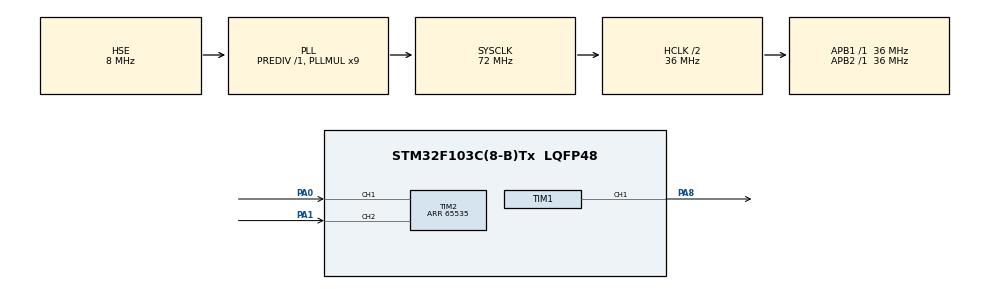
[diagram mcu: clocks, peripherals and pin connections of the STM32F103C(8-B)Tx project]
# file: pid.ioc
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FREERTOS.Tasks01=defaultTask,0,128,StartDefaultTask,Default,NULL
FREERTOS.configTOTAL_HEAP_SIZE=10240
FREERTOS.configUSE_TIMERS=0
Mcu.Family=STM32F1
Mcu.Name=STM32F103C(8-B)Tx
Mcu.Package=LQFP48
NVIC.PriorityGroup=NVIC_PRIORITYGROUP_4
NVIC.TIM2_IRQn=true\:5\:0\:false\:false\:true\:true\:true
PA0-WKUP.Signal=S_TIM2_CH1_ETR
PA1.Signal=S_TIM2_CH2
PA13.Mode=Serial_Wire
PA13.Signal=SYS_JTMS-SWDIO
PA14.Mode=Serial_Wire
PA14.Signal=SYS_JTCK-SWCLK
PA8.Signal=S_TIM1_CH1
PD0-OSC_IN.Mode=HSE-External-Oscillator
PD0-OSC_IN.Signal=RCC_OSC_IN
PD1-OSC_OUT.Mode=HSE-External-Oscillator
PD1-OSC_OUT.Signal=RCC_OSC_OUT
ProjectManager.HeapSize=0x00
ProjectManager.StackSize=0x400
ProjectManager.TargetToolchain=EWARM
RCC.AHBCLKDivider=RCC_SYSCLK_DIV2
RCC.AHBFreq_Value=36000000
RCC.APB1Freq_Value=36000000
RCC.APB1TimFreq_Value=36000000
RCC.APB2Freq_Value=36000000
RCC.APB2TimFreq_Value=36000000
RCC.HCLKFreq_Value=36000000
RCC.PLLMUL=RCC_PLL_MUL9
RCC.PLLSourceVirtual=RCC_PLLSOURCE_HSE
RCC.SYSCLKFreq_VALUE=72000000
RCC.SYSCLKSource=RCC_SYSCLKSOURCE_PLLCLK
RCC.USBFreq_Value=72000000
SH.S_TIM1_CH1.0=TIM1_CH1,PWM Generation1 CH1
SH.S_TIM2_CH1_ETR.0=TIM2_CH1,Encoder_Interface
SH.S_TIM2_CH2.0=TIM2_CH2,Encoder_Interface
TIM1.Channel-PWM\ Generation1\ CH1=TIM_CHANNEL_1
TIM1.Period=999
TIM1.Prescaler=71
TIM2.EncoderMode=TIM_ENCODERMODE_TI12
TIM2.IC1Polarity=TIM_ICPOLARITY_BOTHEDGE
TIM2.IC2Polarity=TIM_ICPOLARITY_BOTHEDGE
TIM2.Period=65535
VP_FREERTOS_VS_ENABLE.Mode=Enabled
board=pid

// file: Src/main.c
/**
  ******************************************************************************
  * File Name          : main.c
  * Description        : Main program body
  ******************************************************************************
  * This notice applies to any and all portions of this file
  * that are not between comment pairs USER CODE BEGIN and
  * USER CODE END. Other portions of this file, whether
  * inserted by the user or by software development tools
  * are owned by their respective copyright owners.
  *
  * Copyright (c) 2017 STMicroelectronics International N.V.
  * All rights reserved.
  *
  * Redistribution and use in source and binary forms, with or without
  * modification, are permitted, provided that the following conditions are met:
  *
  * 1. Redistribution of source code must retain the above copyright notice,
  *    this list of conditions and the following disclaimer.
  * 2. Redistributions in binary form must reproduce the above copyright notice,
  *    this list of conditions and the following disclaimer in the documentation
  *    and/or other materials provided with the distribution.
  * 3. Neither the name of STMicroelectronics nor the names of other
  *    contributors to this software may be used to endorse or promote products
  *    derived from this software without specific written permission.
  * 4. This software, including modifications and/or derivative works of this
  *    software, must execute solely and exclusively on microcontroller or
  *    microprocessor devices manufactured by or for STMicroelectronics.
  * 5. Redistribution and use of this software other than as permitted under
  *    this license is void and will automatically terminate your rights under
  *    this license.
  *
  * THIS SOFTWARE IS PROVIDED BY STMICROELECTRONICS AND CONTRIBUTORS "AS IS"
  * AND ANY EXPRESS, IMPLIED OR STATUTORY WARRANTIES, INCLUDING, BUT NOT
  * LIMITED TO, THE IMPLIED WARRANTIES OF MERCHANTABILITY, FITNESS FOR A
  * PARTICULAR PURPOSE AND NON-INFRINGEMENT OF THIRD PARTY INTELLECTUAL PROPERTY
  * RIGHTS ARE DISCLAIMED TO THE FULLEST EXTENT PERMITTED BY LAW. IN NO EVENT
  * SHALL STMICROELECTRONICS OR CONTRIBUTORS BE LIABLE FOR ANY DIRECT, INDIRECT,
  * INCIDENTAL, SPECIAL, EXEMPLARY, OR CONSEQUENTIAL DAMAGES (INCLUDING, BUT NOT
  * LIMITED TO, PROCUREMENT OF SUBSTITUTE GOODS OR SERVICES; LOSS OF USE, DATA,
  * OR PROFITS; OR BUSINESS INTERRUPTION) HOWEVER CAUSED AND ON ANY THEORY OF
  * LIABILITY, WHETHER IN CONTRACT, STRICT LIABILITY, OR TORT (INCLUDING
  * NEGLIGENCE OR OTHERWISE) ARISING IN ANY WAY OUT OF THE USE OF THIS SOFTWARE,
  * EVEN IF ADVISED OF THE POSSIBILITY OF SUCH DAMAGE.
  *
  ******************************************************************************
  */

#include "main.h"
#include "stm32f1xx_hal.h"
#include "cmsis_os.h"
#include "tim.h"
#include "gpio.h"

/* USER CODE BEGIN PV */
/* Private variables ---------------------------------------------------------*/

/* USER CODE END PV */

void SystemClock_Config(void);
void MX_FREERTOS_Init(void);

/* USER CODE BEGIN PFP */
/* Private function prototypes -----------------------------------------------*/

/* USER CODE END PFP */

int main(void)
{

  /* MCU Configuration----------------------------------------------------------*/

  /* Reset of all peripherals, Initializes the Flash interface and the Systick. */
  HAL_Init();

  /* Configure the system clock */
  SystemClock_Config();

  /* Initialize all configured peripherals */
  MX_GPIO_Init();
  MX_TIM2_Init();
  MX_TIM1_Init();

  /* Call init function for freertos objects (in freertos.c) */
  MX_FREERTOS_Init();

  /* Start scheduler */
  osKernelStart();

  /* We should never get here as control is now taken by the scheduler */

  /* Infinite loop */
  while (1)
  {

  }

}

/** System Clock Configuration
*/
void SystemClock_Config(void)
{

  RCC_OscInitTypeDef RCC_OscInitStruct;
  RCC_ClkInitTypeDef RCC_ClkInitStruct;

    /**Initializes the CPU, AHB and APB busses clocks
    */
  RCC_OscInitStruct.OscillatorType = RCC_OSCILLATORTYPE_HSE;
  RCC_OscInitStruct.HSEState = RCC_HSE_ON;
  RCC_OscInitStruct.HSEPredivValue = RCC_HSE_PREDIV_DIV1;
  RCC_OscInitStruct.HSIState = RCC_HSI_ON;
  RCC_OscInitStruct.PLL.PLLState = RCC_PLL_ON;
  RCC_OscInitStruct.PLL.PLLSource = RCC_PLLSOURCE_HSE;
  RCC_OscInitStruct.PLL.PLLMUL = RCC_PLL_MUL9;
  if (HAL_RCC_OscConfig(&RCC_OscInitStruct) != HAL_OK)
  {
    _Error_Handler(__FILE__, __LINE__);
  }

    /**Initializes the CPU, AHB and APB busses clocks
    */
  RCC_ClkInitStruct.ClockType = RCC_CLOCKTYPE_HCLK|RCC_CLOCKTYPE_SYSCLK
                              |RCC_CLOCKTYPE_PCLK1|RCC_CLOCKTYPE_PCLK2;
  RCC_ClkInitStruct.SYSCLKSource = RCC_SYSCLKSOURCE_PLLCLK;
  RCC_ClkInitStruct.AHBCLKDivider = RCC_SYSCLK_DIV2;
  RCC_ClkInitStruct.APB1CLKDivider = RCC_HCLK_DIV1;
  RCC_ClkInitStruct.APB2CLKDivider = RCC_HCLK_DIV1;

  if (HAL_RCC_ClockConfig(&RCC_ClkInitStruct, FLASH_LATENCY_2) != HAL_OK)
  {
    _Error_Handler(__FILE__, __LINE__);
  }

    /**Configure the Systick interrupt time
    */
  HAL_SYSTICK_Config(HAL_RCC_GetHCLKFreq()/1000);

    /**Configure the Systick
    */
  HAL_SYSTICK_CLKSourceConfig(SYSTICK_CLKSOURCE_HCLK);

  /* SysTick_IRQn interrupt configuration */
  HAL_NVIC_SetPriority(SysTick_IRQn, 15, 0);
}

void _Error_Handler(char * file, int line)
{
  while(1)
  {
  }
}

/************************ (C) COPYRIGHT STMicroelectronics *****END OF FILE****/

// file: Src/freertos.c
/**
  ******************************************************************************
  * File Name          : freertos.c
  * Description        : Code for freertos applications
  ******************************************************************************
  * This notice applies to any and all portions of this file
  * that are not between comment pairs USER CODE BEGIN and
  * USER CODE END. Other portions of this file, whether
  * inserted by the user or by software development tools
  * are owned by their respective copyright owners.
  *
  * Copyright (c) 2017 STMicroelectronics International N.V.
  * All rights reserved.
  *
  * Redistribution and use in source and binary forms, with or without
  * modification, are permitted, provided that the following conditions are met:
  *
  * 1. Redistribution of source code must retain the above copyright notice,
  *    this list of conditions and the following disclaimer.
  * 2. Redistributions in binary form must reproduce the above copyright notice,
  *    this list of conditions and the following disclaimer in the documentation
  *    and/or other materials provided with the distribution.
  * 3. Neither the name of STMicroelectronics nor the names of other
  *    contributors to this software may be used to endorse or promote products
  *    derived from this software without specific written permission.
  * 4. This software, including modifications and/or derivative works of this
  *    software, must execute solely and exclusively on microcontroller or
  *    microprocessor devices manufactured by or for STMicroelectronics.
  * 5. Redistribution and use of this software other than as permitted under
  *    this license is void and will automatically terminate your rights under
  *    this license.
  *
  * THIS SOFTWARE IS PROVIDED BY STMICROELECTRONICS AND CONTRIBUTORS "AS IS"
  * AND ANY EXPRESS, IMPLIED OR STATUTORY WARRANTIES, INCLUDING, BUT NOT
  * LIMITED TO, THE IMPLIED WARRANTIES OF MERCHANTABILITY, FITNESS FOR A
  * PARTICULAR PURPOSE AND NON-INFRINGEMENT OF THIRD PARTY INTELLECTUAL PROPERTY
  * RIGHTS ARE DISCLAIMED TO THE FULLEST EXTENT PERMITTED BY LAW. IN NO EVENT
  * SHALL STMICROELECTRONICS OR CONTRIBUTORS BE LIABLE FOR ANY DIRECT, INDIRECT,
  * INCIDENTAL, SPECIAL, EXEMPLARY, OR CONSEQUENTIAL DAMAGES (INCLUDING, BUT NOT
  * LIMITED TO, PROCUREMENT OF SUBSTITUTE GOODS OR SERVICES; LOSS OF USE, DATA,
  * OR PROFITS; OR BUSINESS INTERRUPTION) HOWEVER CAUSED AND ON ANY THEORY OF
  * LIABILITY, WHETHER IN CONTRACT, STRICT LIABILITY, OR TORT (INCLUDING
  * NEGLIGENCE OR OTHERWISE) ARISING IN ANY WAY OUT OF THE USE OF THIS SOFTWARE,
  * EVEN IF ADVISED OF THE POSSIBILITY OF SUCH DAMAGE.
  *
  ******************************************************************************
  */

#include "FreeRTOS.h"
#include "task.h"
#include "cmsis_os.h"

/* USER CODE BEGIN Includes */
#include "pid.h"
#include "tim.h"
#define APP_LOG_MODULE_NAME "[freertos]"
#include "app_log.h"
#include "SEGGER_RTT.h"
/* USER CODE END Includes */

osThreadId defaultTaskHandle;

/* USER CODE BEGIN Variables */
  arm_pid_instance_t pid_eeprom [1] =
  {{6, 98304, 53084, 1835, 222822, 0, 0}};

  arm_pid_t cat;

/* USER CODE END Variables */

void StartDefaultTask(void const * argument);

void MX_FREERTOS_Init(void); /* (MISRA C 2004 rule 8.1) */

/* Hook prototypes */

/* Init FreeRTOS */

void MX_FREERTOS_Init(void) {

  /* Create the thread(s) */
  /* definition and creation of defaultTask */
  osThreadDef(defaultTask, StartDefaultTask, osPriorityNormal, 0, 128);
  defaultTaskHandle = osThreadCreate(osThread(defaultTask), NULL);

}

/* StartDefaultTask function */
void StartDefaultTask(void const * argument)
{

  /* USER CODE BEGIN StartDefaultTask */
  /* Infinite loop */
 HAL_TIM_Encoder_Start(&htim2,TIM_CHANNEL_1|TIM_CHANNEL_2);
 HAL_TIM_PWM_Start(&htim1, TIM_CHANNEL_1);
 pid_init (&cat,&pid_eeprom[0], 255, (uint32_t*)&htim1.Instance->CCR1, (uint32_t*)&htim1.Instance->CCR1, (uint32_t*)&htim2.Instance->CNT);

  for(;;)
  {
    osDelay(4);
    pid_update(&cat,1);
    int c=SEGGER_RTT_GetKey();
    if(c == 'a')
    {
    APP_LOG_INFO("VL：%d\r\n"  ,cat.pid.VL);
    APP_LOG_INFO("Kf：%d\r\n"  ,cat.pid.Kf);
    APP_LOG_INFO("Kp：%d\r\n"  ,cat.pid.Kp);
    APP_LOG_INFO("Ki：%d\r\n"  ,cat.pid.Ki);
    APP_LOG_INFO("Kd：%d\r\n"  ,cat.pid.Kd);
    APP_LOG_INFO("模式：%d\r\n"  ,cat.servo_mode);
    APP_LOG_INFO("目标点：%d\r\n"  ,cat.setpoint);
    APP_LOG_INFO("实际位置：%d\r\n"  ,cat.feedback);
    APP_LOG_INFO("速度：%d\r\n"  ,cat.velocity);
    APP_LOG_INFO("积分：%d\r\n"  ,cat.integral);
    APP_LOG_INFO("积分限制：%d\r\n"  ,cat.integral_limit);

    APP_LOG_INFO("上次误差：%d\r\n"  ,cat.last_error);
    APP_LOG_INFO("上次位置：%d\r\n"  ,cat.last_position);
    APP_LOG_INFO("最大PWM值：%d\r\n"  ,cat.pwm_max_val);
    APP_LOG_INFO("当前PWM值：%d\r\n"  ,(uint32_t) *cat.pwm_p);
    APP_LOG_INFO("当前编码器值：%d\r\n"  ,(uint32_t)*cat.encoder);
    }
  }
  /* USER CODE END StartDefaultTask */
}

/************************ (C) COPYRIGHT STMicroelectronics *****END OF FILE****/
